# netx90_app register map
File version: 1.0
CPU: CM4 r0p1, little endian, MPU, FPU, 4 interrupt priority bits, 78 interrupts
Registers are 32-bit, read-write, reset 0x0 unless marked. A register's access mark holds for its fields unless they carry their own. Offsets are from the block's base; [hi:lo] are bit positions; {n}, {i} and the like mark numbered series; 'fields as' and 'values as' point back to an identical list.

## endat_ctrl0_app
Base 0xFF802080
Same registers: endat_ctrl1_app 0xFF802090
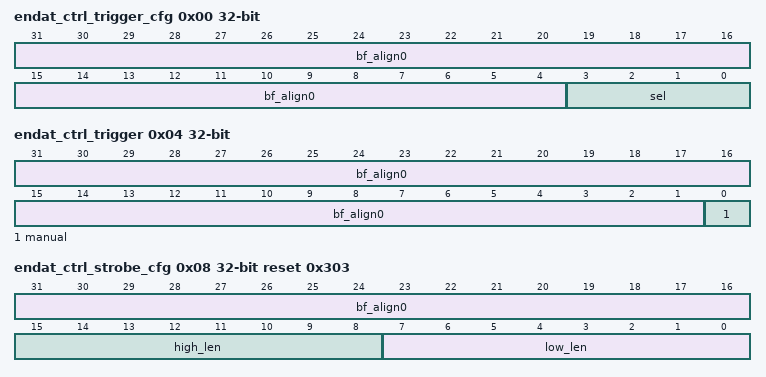
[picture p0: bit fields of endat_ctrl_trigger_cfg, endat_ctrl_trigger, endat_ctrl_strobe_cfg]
0x00 endat_ctrl_trigger_cfg (reset mask 0xF) — EnDat trigger configuration
  [31:4] bf_align0 — bitField alignment value for aeabi compatibility
  [3:0] sel — Trigger source select This bit field configures which event is connected to the strobe signal of the EnDat core. A rising edge of the selected event will generate an event to the core according to the configuration in the strobe_cfg register. Note: When ntimer or n_si are selected, they are routed directly to the EnDat core (i.e. they are not connected to the pulse former). { | Value trigger event 0 none 1 manual 2 xc_trigger_out0 3 xc_trigger_out0 (inverted) 4 xc_trigger_out1 5 xc_trigger_out1 (inverted) 6 xc_sample_in0 7 xc_sample_in0 (inverted) 8 xc_sample_in1 9 xc_sample_in1 (inverted) 10 gpio_app_counter_zero0 11 gpio_app_counter_zero1 12 gpio_app_counter_zero2 13 ntimer signal of other EnDat instance 14 n_si signal of other EnDat instance 15 reserved }
0x04 endat_ctrl_trigger (reset mask 0x1) — EnDat trigger
  [31:1] bf_align0 — bitField alignment value for aeabi compatibility
  [0] manual — Manual trigger. Writing '1' to this bit will trigger the EnDat core immediately in case the trigger_cfg.sel bit field is set to manual mode and the EnDat core is setup for external triggering by the strobe signal.
0x08 endat_ctrl_strobe_cfg reset 0x303 (reset mask 0xFFFF) — EnDat strobe pulse form configuration
  [31:16] bf_align0 — bitField alignment value for aeabi compatibility
  [15:8] high_len — Length of the high phase (i.e. inactive phase) of the strobe signal The high phase will be the programmed value + 1 clock cycle. Note: EnDat spec requires the high phase to be at least 4 clock cycles long, therefore 0 - 2 are illegal settings. Note: There is no other requirement on the high phase. This bit field is for debug and test only and should be kept at its default setting.
  [7:0] low_len — Length of the low phase (i.e. active phase) of the strobe signal The low phase will be the programmed value + 1 clock cycle. Note: EnDat spec requires the low phase to be at least 4 clock cycles long, therefore 0 - 2 are illegal settings. Note: If a strobe delay is configured in the EnDat core, the minimum length is strobe delay + 1 (i.e. program low_len = strobe delay).

## biss_ctrl0_app
Base 0xFF8020A0
Same registers: biss_ctrl1_app 0xFF8020C0
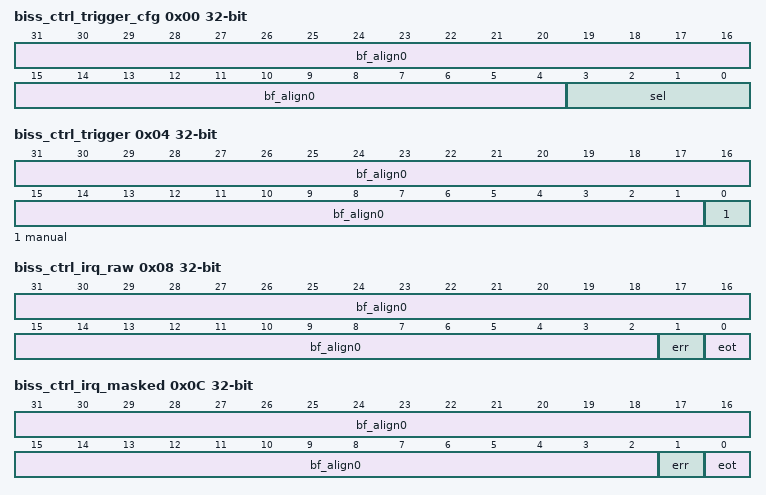
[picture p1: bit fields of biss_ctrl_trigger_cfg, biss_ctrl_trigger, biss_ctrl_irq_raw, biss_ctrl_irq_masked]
0x00 biss_ctrl_trigger_cfg (reset mask 0xF) — BiSS trigger configuration
  [31:4] bf_align0 — bitField alignment value for aeabi compatibility
  [3:0] sel — Trigger source select This bit field configures which event is connected to the GETSENS signal of the BiSS core. A rising edge of the selected event will generate an event to the core. { | Value trigger event 0 none 1 manual 2 xc_trigger_out0 3 xc_trigger_out0 (inverted) 4 xc_trigger_out1 5 xc_trigger_out1 (inverted) 6 xc_sample_in0 7 xc_sample_in0 (inverted) 8 xc_sample_in1 9 xc_sample_in1 (inverted) 10 gpio_app_counter_zero0 11 gpio_app_counter_zero1 12 gpio_app_counter_zero2 13-15 reserved }
0x04 biss_ctrl_trigger (reset mask 0x1) — BiSS trigger
  [31:1] bf_align0 — bitField alignment value for aeabi compatibility
  [0] manual — Manual trigger. Writing '1' to this bit will trigger the BiSS core immediately in case the trigger_cfg.sel bit field is set to manual mode and the BiSS core is setup for external triggering by the GETSENS signal.
0x08 biss_ctrl_irq_raw (reset mask 0x3) — BiSS raw IRQ: Read access shows status of unmasked IRQs. IRQs are set automatically and reset by writing to this register: Write access with '1' resets the appropriate IRQ. Write access with '0' does not influence this bit.
  [31:2] bf_align0 — bitField alignment value for aeabi compatibility
  [1] err — Error signal from the BiSS core. Only a falling edge on the NER signal will set the interrupt.
  [0] eot — End-Of-Transmission signal from the BiSS core. Only a rising edge on the EOT signal will set the interrupt.
0x0C biss_ctrl_irq_masked ro (reset mask 0x3) — BiSS masked IRQ: Shows status of masked IRQs.
  [31:2] bf_align0 — bitField alignment value for aeabi compatibility
  [1] err — Error signal from the BiSS core.
  [0] eot — End-Of-Transmission signal from the BiSS core.
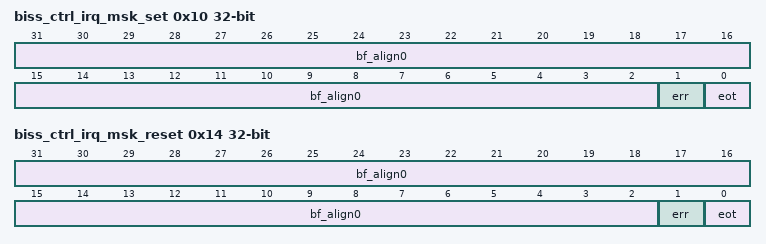
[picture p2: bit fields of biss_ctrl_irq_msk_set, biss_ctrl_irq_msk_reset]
0x10 biss_ctrl_irq_msk_set (reset mask 0x3) — BiSS IRQ mask set: The IRQ mask enables interrupt requests for corresponding interrupt sources. As its bits might be changed by different software tasks, the IRQ mask register is not writable directly, but by set and reset masks: Write access with '1' sets interrupt mask bit. Write access with '0' does not influence this bit. Read access shows actual interrupt mask. Attention: Before activating interrupt mask, delete old pending interrupts by writing the same value to mtgy_irq_raw.
  fields as biss_ctrl_irq_masked
0x14 biss_ctrl_irq_msk_reset (reset mask 0x3) — BiSS IRQ mask reset: This is the corresponding reset mask to disable interrupt requests for corresponding interrupt sources: Write access with '1' resets interrupt mask bit. Write access with '0' does not influence this bit. Read access shows actual interrupt mask.
  fields as biss_ctrl_irq_masked
